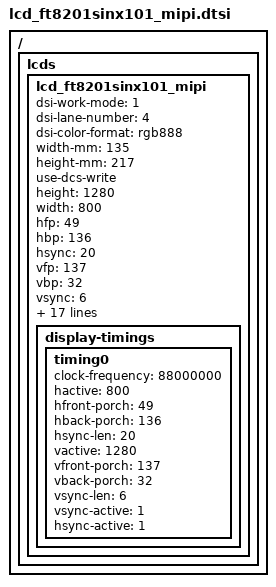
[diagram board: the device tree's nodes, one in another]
// SPDX-License-Identifier: GPL-2.0

/ { lcds: lcds {
	lcd_ft8201sinx101_mipi: lcd_ft8201sinx101_mipi {
		dsi-work-mode = <1>; /* video burst mode*/
		dsi-lane-number = <4>;
		dsi-color-format = "rgb888";
		width-mm = <135>;
		height-mm = <217>;
		use-dcs-write;

		/*mipi info*/
		height = <1280>;
		width = <800>;
		hfp = <49>;
		hbp = <136>;
		hsync = <20>;
		vfp = <137>;
		vbp = <32>;
		vsync = <6>;
		fps = <60>;
		work-mode = <0>;
		rgb-mode = <3>;
		lane-number = <4>;
		phy-bit-clock = <614000000>;
		split-enable = <0>;
		eotp-enable = <0>;
		burst-mode = <2>;
		esd-check-enable = <0>;

		/* DSI_CMD, DSI_MODE, timeout, len, cmd */
		initial-command = [
			39 01 00 02 41 5A
			// blank 8
			39 01 00 03 41 5A 08
			39 01 00 05 80 82 00 82 00
			// blank 9
			39 01 00 03 41 5A 09
			39 01 00 11 80 1A 01 AB 93 A5 97 59 2A B1 06 00 00 80 1F 80 10
			39 01 00 11 90 42 44 84 14 C6 13 99 09 C0 BB 0A 0F 07 E0 2A 00
			39 01 00 11 A0 80 90 20 AA 00 04 55 55 05 00 1F 15 42 00 FE FF
			39 01 00 11 B0 03 39 6D 01 D3 05 D3 05 00 00 30 41 25 00 4A 00
			39 01 00 11 C0 00 00 00 00 00 00 00 00 10 04 02 00 07 00 08 18
			39 01 00 03 D0 00 00
			// blank 10
			39 01 00 03 41 5A 0A
			39 01 00 11 80 91 91 D4 30 36 23 2D 34 3C 4A 56 57 63 66 7D 83
			39 01 00 11 90 6D 6C 5F 56 4A 3A 30 27 15 0F 0A 30 36 23 2D 34
			39 01 00 11 A0 3C 4A 56 57 63 66 7D 83 6D 6C 5F 56 4A 3A 30 27
			39 01 00 04 B0 15 0F 0A
			// blank 11
			39 01 00 03 41 5A 0B
			39 01 00 11 80 00 00 50 B5 C5 AC 00 00 A0 6A 8B A9 AE 22 02 00
			39 01 00 11 90 EF D8 B8 F7 25 70 E0 08 11 02 40 13 4F 4D 3C 35
			39 01 00 09 A0 F1 A4 06 FF FF 00 03 00
			// blank 12
			39 01 00 03 41 5A 0C
			39 01 00 11 80 FA 68 90 01 28 05 7A 05 00 00 56 01 00 55 61 15
			39 01 00 11 90 55 51 15 56 01 00 56 01 00 55 61 15 55 51 15 56
			39 01 00 11 A0 B1 84 01 50 00 50 00 50 00 40 94 02 00 00 00 30
			39 01 00 11 B0 28 15 80 04 00 18 00 00 00 30 0A 00 00 00 00 00
			39 01 00 08 C0 00 01 05 C2 B0 00 00
			// blank 13
			39 01 00 03 41 5A 0D
			39 01 00 11 80 08 00 00 28 02 00 04 12 00 08 02 77 02 4A 10 F0
			39 01 00 07 90 00 02 58 16 04 A1
			// blank 14
			39 01 00 03 41 5A 0E
			39 01 00 11 80 FF 81 68 6C 22 FD 22 00 55 55 55 55 05 5A 5A 80
			39 01 00 07 90 01 00 00 60 01 00
			// blank 15
			39 01 00 03 41 5A 0F
			39 01 00 11 80 01 D5 C1 24 52 00 50 00 00 06 28 06 1C 00 3C 82
			39 01 00 11 90 1D 60 21 40 03 04 48 A0 05 5A 10 00 00 10 84 D0
			39 01 00 11 A0 37 80 43 B3 1D C0 4A 0B 5A 71 22 80 19 4A 00 20
			39 01 00 11 B0 27 9E 01 C0 19 7A 21 14 00 40 30 E0 00 2D D0 82
			39 01 00 11 C0 00 00 80 20 84 A0 21 1A 9A 21 02 10 62 84 28 03
			39 01 00 11 D0 8A 88 88 48 92 09 0F 15 1E E0 31 06 04 02 14 04
			39 01 00 11 E0 10 22 22 7D AD 05 D6 42 B5 28 1E D2 62 40 41 00
			39 01 00 10 F0 00 11 10 04 F5 FF FF 3F 00 00 15 40 14 00 00
			// blank 16
			39 01 00 03 41 5A 10
			39 01 00 11 80 00 00 03 E7 8F 0B 10 28 00 A9 66 0C 18 C4 20 C5
			39 01 00 11 90 1C 94 D4 62 CD 3D F8 03 3F F0 03 3F 00 FF FF FF
			39 01 00 03 A0 81 00
			// blank 17
			39 01 00 03 41 5A 11
			39 01 00 08 80 00 00 00 00 00 00 00
			// blank 18
			39 01 00 03 41 5A 12
			39 01 00 11 80 00 00 00 00 00 00 00 00 00 00 00 00 00 00 00 00
			39 01 00 11 90 00 10 00 00 00 00 00 00 00 00 00 00 00 00 00 00
			39 01 00 11 A0 00 00 00 00 00 00 2D 23 05 FB 00 2D 23 05 FB 00
			39 01 00 08 B0 01 00 00 00 00 00 00
			// blank 19
			39 01 00 03 41 5A 13
			39 01 00 11 80 00 08 80 15 00 90 10 18 3E 10 00 D6 03 04 18 00
			39 01 00 11 90 70 88 30 90 32 70 3E 97 8B 39 30 C4 09 C4 09 C4
			39 01 00 11 A0 89 4F DC 45 80 0A C4 09 C4 09 80 02 00 00 00 00
			39 01 00 11 B0 00 00 00 00 00 00 1B 01 31 75 B9 42 86 CA 31 75
			39 01 00 11 C0 B9 42 86 CA 00 00 00 00 0C 60 00 24 18 00 09 06
			39 01 00 11 D0 40 82 01 90 60 00 24 D0 01 09 74 40 02 1D 90 40
			39 01 00 11 E0 07 24 D0 01 09 1E 46 1E 46 00 00 20 C5 0F 00 C0
			39 01 00 0D F0 10 40 26 4E 46 02 C8 20 80 0C 00 00
			// blank 20
			39 01 00 03 41 5A 14
			39 01 00 11 80 01 02 40 2C 99 DF EF F7 23 A7 03 00 00 80 82 78
			39 01 00 11 90 F0 FB 11 B0 07 7E 3F 02 36 C1 EF 47 C0 26 F8 FD
			39 01 00 11 A0 08 D8 0C BF 1F 01 9B E1 F7 23 00 00 05 00 00 00
			39 01 00 11 B0 00 00 00 00 00 00 00 00 00 00 02 00 80 0B 05 0B
			39 01 00 11 C0 05 05 00 30 18 0C D7 01 B2 97 04 C5 00 74 05 20
			39 01 00 11 D0 7B 49 50 0C 40 57 02 B2 97 04 C5 00 74 45 20 7B
			39 01 00 11 E0 49 50 0C 40 57 06 B2 97 04 C5 00 74 85 20 7B 49
			39 01 00 11 F0 50 0C 40 57 0A B2 97 04 C5 00 74 C5 20 7B 49 50
			// blank 21
			39 01 00 03 41 5A 15
			39 01 00 11 80 0C 40 40 80 DF 0F 00 00 00 00 00 00 00 00 00 00
			39 01 00 11 90 00 00 00 00 00 00 00 00 00 00 00 00 00 00 00 00
			39 01 00 11 A0 00 00 00 00 00 00 00 00 00 00 00 00 00 00 00 00
			39 01 00 11 B0 00 00 00 00 00 00 00 00 00 00 00 00 00 00 00 00
			39 01 00 11 C0 00 00 00 00 00 00 00 00 00 60 11 00 E0 01 50 5A
			39 01 00 11 D0 93 92 3E 4E 41 0C 42 00 A0 B6 6D DB B6 6D DB B6
			39 01 00 11 E0 6D 5B B3 8A 3E 2E 59 82 A1 38 A6 B6 6D DB B6 6D
			39 01 00 11 F0 DB B6 6D 5B B3 9A 3E 6E 49 8E 62 08 A2 B6 6D DB
			// blank 22
			39 01 00 03 41 5A 16
			39 01 00 11 80 B6 6D DB B6 6D 5B 93 82 3E 0E 51 00 81 30 A4 B6
			39 01 00 11 90 6D DB B6 6D DB B6 6D 01 03 03 00 00 00 00 00 00
			39 01 00 11 A0 00 00 00 00 00 00 00 00 00 00 00 00 C0 1F E1 01
			39 01 00 11 B0 28 02 00 00 00 00 00 00 00 00 04 00 00 00 00 00
			39 01 00 11 C0 00 00 00 00 00 00 02 02 00 00 00 00 00 00 02 00
			39 01 00 11 D0 00 00 00 00 00 00 00 00 04 00 00 00 00 00 00 00
			39 01 00 11 E0 00 00 00 00 01 00 00 00 00 00 00 00 00 00 00 00
			39 01 00 11 F0 00 04 00 00 00 00 00 00 00 00 00 20 00 00 00 00
			// blank 23
			39 01 00 03 41 5A 17
			39 01 00 11 80 00 00 00 00 00 04 00 00 00 00 00 00 00 00 00 20
			39 01 00 11 90 00 00 00 00 00 00 00 00 00 10 00 00 00 00 00 00
			39 01 00 11 A0 00 00 00 00 00 00 00 10 00 00 00 00 00 00 00 00
			39 01 00 11 B0 40 00 00 00 00 00 00 00 00 00 01 00 00 00 00 00
			39 01 00 11 C0 00 00 00 00 10 00 00 00 00 00 00 00 00 00 00 00
			39 01 00 07 D0 00 01 00 00 00 00
			// blank 24
			39 01 00 03 41 5A 18
			39 01 00 11 80 7F 7F FE FE FE FE FE FE FE FE FE FE D4 7F D4 D4
			39 01 00 11 90 D4 D4 D4 D4 D4 D4 D4 D4 AA AA AA AA AA AA AA AA
			39 01 00 11 A0 AA AA AA AA 7F 7F 7F 7F 7F 7F 7F 7F 7F 7F 7F 7F
			39 01 00 11 B0 7C 83 79 86 79 86 79 86 79 86 79 86 7A 83 7A 85
			39 01 00 11 C0 7A 85 7A 85 7A 85 7A 85 7B 84 7B 84 7B 84 7B 84
			39 01 00 11 D0 7B 84 7B 84 7C 83 7C 83 7C 83 7C 83 7C 83 7C 83
			39 01 00 11 E0 FE 7F 7F FE FE FE FE FE FE FE FE FE FE D4 7F D4
			39 01 00 11 F0 D4 D4 D4 D4 D4 D4 D4 D4 D4 AA AA AA AA AA AA AA
			// blank 25
			39 01 00 03 41 5A 19
			39 01 00 11 80 AA AA AA AA AA 7F 7F 7F 7F 7F 7F 7F 7F 7F 7F 7F
			39 01 00 11 90 7F 7C 83 79 86 79 86 79 86 79 86 79 86 7A 83 7A
			39 01 00 11 A0 85 7A 85 7A 85 7A 85 7A 85 7B 84 7B 84 7B 84 7B
			39 01 00 11 B0 84 7B 84 7B 84 7C 83 7C 83 7C 83 7C 83 7C 83 7C
			39 01 00 11 C0 83 7F 04 FF 1E 00 08 10 18 20 28 30 38 FC 00 04
			39 01 00 0C D0 20 00 01 08 40 00 02 10 80 00 FC
			// blank 26
			39 01 00 03 41 5A 1A
			39 01 00 11 80 F0 D9 C8 BA AF A6 9E 98 92 8D 88 84 00 60 F6 CF
			39 01 00 11 90 FC 6F F6 EF CF AF 5F 55 00 F8 00 F8 00 F8 AD 8D
			39 01 00 11 A0 73 60 53 4A 43 7F 78 10 A0 3F 00 00 00 00 00 00
			39 01 00 11 B0 00 00 00 00 00 00 00 00 00 00 00 00 00 00 00 00
			39 01 00 09 C0 00 00 00 00 00 00 00 00
			// blank 28
			39 01 00 03 41 5A 1C
			39 01 00 11 80 00 04 08 0C 00 10 14 18 1C 00 20 28 30 38 00 40
			39 01 00 11 90 48 50 58 00 60 68 70 78 00 80 88 90 98 00 A0 A8
			39 01 00 11 A0 B0 B8 00 C0 C8 D0 D8 00 E0 E8 F0 F8 00 FC FE FF
			39 01 00 11 B0 00 00 04 08 0C 00 10 14 18 1C 00 20 28 30 38 00
			39 01 00 11 C0 40 48 50 58 00 60 68 70 78 00 80 88 90 98 00 A0
			39 01 00 11 D0 A8 B0 B8 00 C0 C8 D0 D8 00 E0 E8 F0 F8 00 FC FE
			39 01 00 11 E0 FF 00 00 04 08 0C 00 10 14 18 1C 00 20 28 30 38
			39 01 00 11 F0 00 40 48 50 58 00 60 68 70 78 00 80 88 90 98 00
			// blank 29
			39 01 00 03 41 5A 1D
			39 01 00 11 80 A0 A8 B0 B8 00 C0 C8 D0 D8 00 E0 E8 F0 F8 00 FC
			39 01 00 05 90 FE FF 00 00
			// blank 31
			39 01 00 03 41 5A 1F
			39 01 00 11 80 5A 0F 70 09 28 30 38 40 48 50 58 60 20 30 38 40
			39 01 00 11 90 48 50 58 60 20 28 38 40 48 50 58 60 20 28 30 40
			39 01 00 11 A0 48 50 58 60 20 28 30 38 48 50 58 60 20 28 30 38
			39 01 00 11 B0 40 50 58 60 20 28 30 38 40 48 58 60 20 28 30 38
			39 01 00 11 C0 40 48 50 60 20 28 30 38 40 48 50 58 FF 5A 1E 20
			39 01 00 0D D0 00 02 20 00 02 20 00 02 20 00 02 FE
			// blank 32
			39 01 00 03 41 5A 20
			39 01 00 11 80 44 73 03 00 CA F3 FF 6B 10 08 02 08 03 41 18 30
			39 01 00 11 90 18 44 E1 40 E1 20 30 18 C8 21 41 01 39 13 44 42
			39 01 00 11 A0 91 50 28 14 0A 85 03 D2 B0 80 36 7F D0 1F 12 E0
			39 01 00 11 B0 18 36 1B 11 04 20 02 D0 80 B3 21 38 20 18 88 03
			39 01 00 11 C0 82 01 41 70 40 30 8D 0D A4 A2 00 80 04 38 00 50
			39 01 00 11 D0 80 13 E0 00 14 C0 70 40 00 E0 81 00 00 28 0E 06
			39 01 00 11 E0 43 55 55 55 55 55 D5 CC CC CC CC CC 4C 08 82 C6
			39 01 00 11 F0 E0 01 00 00 00 21 42 88 00 00 00 00 00 00 00 20
			// blank 33
			39 01 00 03 41 5A 21
			39 01 00 11 80 04 41 06 49 90 04 49 00 00 49 00 00 49 00 00 49
			39 01 00 11 90 90 04 00 85 11 0C 00 00 40 00 00 00 00 16 00 A5
			39 01 00 11 A0 00 08 08 15 10 D1 B6 45 92 8A 20 A2 6D 0B 00 54
			39 01 00 11 B0 40 44 DB 16 00 48 92 24 09 E0 0F 80 55 30 01 10
			39 01 00 11 C0 01 42 82 11 20 02 10 10 01 08 88 00 04 44 00 02
			39 01 00 11 D0 22 00 04 91 80 1F 00 40 40 04 00 00 00 18 10 16
			39 01 00 03 E0 10 00
			// blank 34
			39 01 00 03 41 5A 22
			39 01 00 11 80 29 D3 00 55 55 55 55 55 55 55 55 55 55 55 1F 70
			39 01 00 04 90 F0 00 00
			// blank 35
			39 01 00 03 41 5A 23
			39 01 00 11 80 09 01 02 05 00 05 04 00 00 00 00 00 00 00 00 00
			39 01 00 0A 90 00 FF 1F 20 00 01 00 00 FE
			// blank 36
			39 01 00 03 41 5A 24
			39 01 00 11 80 00 03 00 FF FF 66 00 00 00 00 00 00 00 00 5B 26
			39 01 00 0F 90 5A A5 5A 00 00 00 00 22 22 3A 22 00 00 00
			// spi finish
			39 01 00 03 41 5A 24
			39 01 00 02 90 A5
			// blank select 2f
			39 01 00 03 41 5A 2F
			// cancel tp i2c mode
			39 01 00 02 4C 03
			// bypass or fifo mode
			39 01 00 02 09 01
			// set led pwm
			39 01 00 03 51 FF 0F
			39 01 00 02 53 24
			39 01 00 02 55 00
			// bist mode
			// 39 01 00 02 02 5A
			39 01 78 02 11 00
			39 01 32 02 29 00
		];
		sleep-in-command = [
			39 01 78 01 28
			39 01 32 01 10
		];
		sleep-out-command = [
			39 01 78 01 11
			39 01 32 01 29
		];
		read-id-command = [
			37 01 00 01 02
			14 01 00 01 DA DB
		];

		display-timings {
			timing0 {
				clock-frequency = <88000000>;
				hactive = <800>;
				hfront-porch = <49>;
				hback-porch = <136>;
				hsync-len = <20>;
				vactive = <1280>;
				vfront-porch = <137>;
				vback-porch = <32>;
				vsync-len = <6>;
				vsync-active = <1>;
				hsync-active = <1>;
			};
		};
	};
};};
